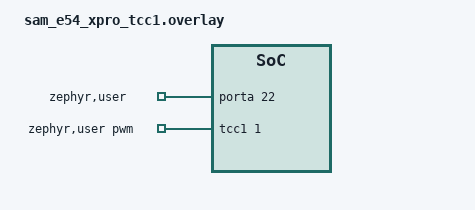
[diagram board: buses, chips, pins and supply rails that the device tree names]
/*
 * SPDX-FileCopyrightText: Copyright 2026 Microchip Technology Inc.
 * SPDX-License-Identifier: Apache-2.0
 */

/* connect PA22 to PA23 */

#define PWM_NODE    tcc1
#define PWM_PINCTRL tcc1_pwm_default
#define PWM_COMPAT "microchip,tcc-g1-pwm"
#include "mchp_pwm_loopback_support.dtsi"

/ {
	zephyr,user {
		pwms = <&tcc1 1 PWM_MSEC(20) 0>;
		gpios = <&porta 22 GPIO_ACTIVE_HIGH>;
	};
};

&porta {
	status = "okay";
};

&pinctrl {
	tcc1_pwm_default: tcc1_pwm_default {
		group1 {
			pinmux = <PA22F_TCC1_WO6>;
		};
	};
};
